# GD32E53x register map
File version: 1.0
CPU: CM33 r0p4, little endian, MPU, FPU, 4 interrupt priority bits
Registers are 32-bit, read-write, reset 0x0 unless marked. A register's access mark holds for its fields unless they carry their own. Offsets are from the block's base; [hi:lo] are bit positions.

## PMU — Power management unit
Base 0x40007000
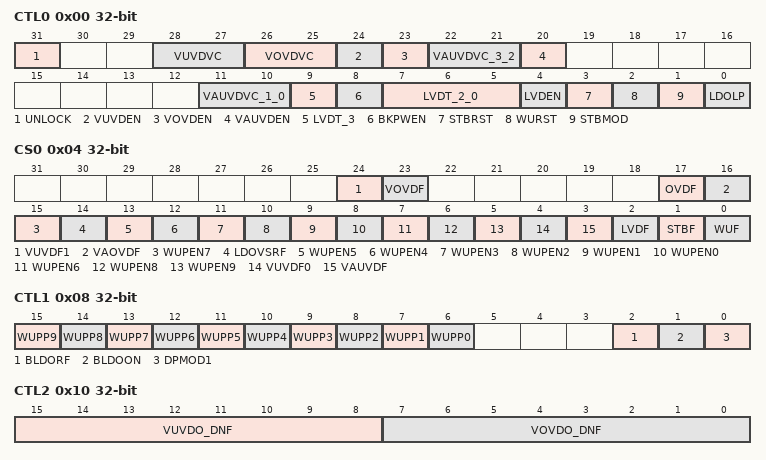
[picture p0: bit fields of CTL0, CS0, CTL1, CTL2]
0x00 CTL0 — Control register 0
  [31] UNLOCK — Register lock
  [28:27] VUVDVC — VCORE under voltage detector voltage level configure bits (VDD reset)
  [26:25] VOVDVC — VCORE over voltage detector voltage level configure bits
  [24] VUVDEN — VCORE under Voltage detector enable
  [23] VOVDEN — VCORE over Voltage detector enable
  [22:21] VAUVDVC_3_2 — combination with 11:10 bits
  [20] VAUVDEN — VDDA analog voltage detector voltage enable bit
  [11:10] VAUVDVC_1_0 — VDDA analog voltage detector voltage level configure bits
  [9] LVDT_3 — combination with 7:5 bits
  [8] BKPWEN — Backup Domain Write Enable
  [7:5] LVDT_2_0 — Low Voltage Detector Threshold
  [4] LVDEN — Low Voltage Detector Enable
  [3] STBRST — Standby Flag Reset
  [2] WURST — Wakeup Flag Reset
  [1] STBMOD — Standby Mode
  [0] LDOLP — LDO Low Power Mode
0x04 CS0 access per field — Control and status register 0
  [24] VUVDF1 ro — VCORE under voltage detector flag bit after digital filter.
  [23] VOVDF ro — VCORE over voltage detector flag bit after digital filter.
  [17] OVDF ro — VDD Over Voltage Detector Status Flag
  [16] VAOVDF ro — VDDA analog voltage detector over voltage output status flag
  [15] WUPEN7 rw — WKUP Pin7(PB9) Enable
  [14] LDOVSRF ro — LDO voltage select ready flag
  [13] WUPEN5 rw — WKUP Pin5(PB5) Enable
  [12] WUPEN4 rw — WKUP Pin4(PC5) Enable
  [11] WUPEN3 rw — WKUP Pin3(PA2) Enable
  [10] WUPEN2 rw — WKUP Pin2(PE6) Enable
  [9] WUPEN1 rw — WKUP Pin1(PC13) Enable
  [8] WUPEN0 rw — WKUP Pin0(PA0) Enable
  [7] WUPEN6 rw — WKUP Pin6(PB15) Enable
  [6] WUPEN8 rw — WKUP Pin8(PD4) Enable
  [5] WUPEN9 rw — WKUP Pin9(PD9) Enable
  [4] VUVDF0 rw — Record the undervoltage reset of the VCORE
  [3] VAUVDF ro — VDDA analog voltage detector voltage output on VDDA flag bit.
  [2] LVDF ro — Low Voltage Detector Status Flag
  [1] STBF ro — Standby Flag
  [0] WUF ro — Wakeup Flag
0x08 CTL1 — Control register 1
  [15] WUPP9 — Polarity selection for the WKUP pin (PD9)
  [14] WUPP8 — Polarity selection for the WKUP pin (PD4)
  [13] WUPP7 — Polarity selection for the WKUP pin (PB9)
  [12] WUPP6 — Polarity selection for the WKUP pin (PB15)
  [11] WUPP5 — Polarity selection for the WKUP pin (PB5)
  [10] WUPP4 — Polarity selection for the WKUP pin (PC5)
  [9] WUPP3 — Polarity selection for the WKUP pin (PA2)
  [8] WUPP2 — Polarity selection for the WKUP pin (PE6)
  [7] WUPP1 — Polarity selection for the WKUP pin (PC13)
  [6] WUPP0 — Polarity selection for the WKUP pin (PA0)
  [2] BLDORF — Backup voltage stabilizer ready flag
  [1] BLDOON — Backup voltage stabilizer enable
  [0] DPMOD1 — Deep-sleep 1 mode enable
0x0C CS1 — Control and status register 1
  [0] DPF1 — Deep-sleep1 mode status flag.
0x10 CTL2 — Control register 2
  [15:8] VUVDO_DNF — VUVD analog output digital noise filter
  [7:0] VOVDO_DNF — VOVD analog output digital noise filter
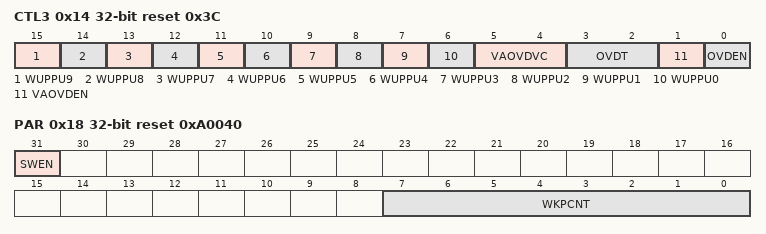
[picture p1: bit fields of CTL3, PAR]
0x14 CTL3 reset 0x3C — Control register 3
  [15] WUPPU9 — The WKUP pin (PD9) can be selected by pulling up and down
  [14] WUPPU8 — The WKUP pin (PD4) can be selected by pulling up and down
  [13] WUPPU7 — The WKUP pin (PB9) can be selected by pulling up and down
  [12] WUPPU6 — The WKUP pin (PB15) can be selected by pulling up and down
  [11] WUPPU5 — The WKUP pin (PB5) can be selected by pulling up and down
  [10] WUPPU4 — The WKUP pin (PC5) can be selected by pulling up and down
  [9] WUPPU3 — The WKUP pin (PA2) can be selected by pulling up and down
  [8] WUPPU2 — The WKUP pin (PE6) can be selected by pulling up and down
  [7] WUPPU1 — The WKUP pin (PC13) can be selected by pulling up and down
  [6] WUPPU0 — The WKUP pin (PA0) can be selected by pulling up and down
  [5:4] VAOVDVC — VDDA overvoltage threshold selection signal, monitoring VDDA voltage
  [3:2] OVDT — LVD overvoltage threshold selection signal, monitoring VDD voltage
  [1] VAOVDEN — VDDA overvoltage detection enable signal
  [0] OVDEN — LVD overvoltage detection enable signal
0x18 PAR reset 0xA0040 — Parameter register
  [31] SWEN — Use configuration value when exit deep-sleep1
  [7:0] WKPCNT — Wakeup time of deep-sleep1
